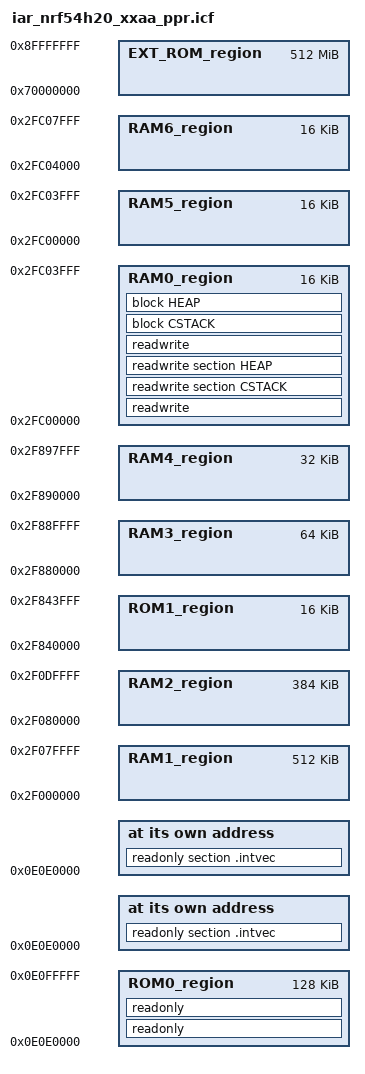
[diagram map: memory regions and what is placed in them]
/*###ICF### Section handled by ICF editor, don't touch! ****/
/*-Editor annotation file-*/
/* IcfEditorFile="$TOOLKIT_DIR$\config\ide\IcfEditor\cortex_v1_0.xml" */
/*-Specials-*/
define symbol __ICFEDIT_intvec_start__ = 0x0E0E0000;
/*-Memory Regions-*/
define symbol __ICFEDIT_region_ROM0_start__   = 0x0E0E0000;
define symbol __ICFEDIT_region_ROM0_end__     = 0x0E0FFFFF;
define symbol __ICFEDIT_region_ROM1_start__   = 0x2F840000;
define symbol __ICFEDIT_region_ROM1_end__     = 0x2F843FFF;
define symbol __ICFEDIT_region_EXT_ROM_start__   = 0x70000000;
define symbol __ICFEDIT_region_EXT_ROM_end__     = 0x8FFFFFFF;
define symbol __ICFEDIT_region_RAM0_start__   = 0x2FC00000;
define symbol __ICFEDIT_region_RAM0_end__     = 0x2FC03FFF;
define symbol __ICFEDIT_region_RAM1_start__   = 0x2F000000;
define symbol __ICFEDIT_region_RAM1_end__     = 0x2F07FFFF;
define symbol __ICFEDIT_region_RAM2_start__   = 0x2F080000;
define symbol __ICFEDIT_region_RAM2_end__     = 0x2F0DFFFF;
define symbol __ICFEDIT_region_RAM3_start__   = 0x2F880000;
define symbol __ICFEDIT_region_RAM3_end__     = 0x2F88FFFF;
define symbol __ICFEDIT_region_RAM4_start__   = 0x2F890000;
define symbol __ICFEDIT_region_RAM4_end__     = 0x2F897FFF;
define symbol __ICFEDIT_region_RAM5_start__   = 0x2FC00000;
define symbol __ICFEDIT_region_RAM5_end__     = 0x2FC03FFF;
define symbol __ICFEDIT_region_RAM6_start__   = 0x2FC04000;
define symbol __ICFEDIT_region_RAM6_end__     = 0x2FC07FFF;

/*-Sizes-*/
define symbol __ICFEDIT_size_cstack__   = 0x800;
define symbol __ICFEDIT_size_heap__     = 0x800;
/**** End of ICF editor section. ###ICF###*/

define memory mem with size = 4G;
define region ROM0_region = mem:[from __ICFEDIT_region_ROM0_start__   to __ICFEDIT_region_ROM0_end__]; /* Inside global MRAM0 */
define region ROM1_region = mem:[from __ICFEDIT_region_ROM1_start__   to __ICFEDIT_region_ROM1_end__]; /* OTP0 */
define region EXT_ROM_region = mem:[from __ICFEDIT_region_EXT_ROM_start__   to __ICFEDIT_region_EXT_ROM_end__];
define region RAM0_region = mem:[from __ICFEDIT_region_RAM0_start__   to __ICFEDIT_region_RAM0_end__]; /* All of GRAM30 */
define region RAM1_region = mem:[from __ICFEDIT_region_RAM1_start__   to __ICFEDIT_region_RAM1_end__]; /* RAM00 */
define region RAM2_region = mem:[from __ICFEDIT_region_RAM2_start__   to __ICFEDIT_region_RAM2_end__]; /* RAM01 */
define region RAM3_region = mem:[from __ICFEDIT_region_RAM3_start__   to __ICFEDIT_region_RAM3_end__]; /* RAM20 */
define region RAM4_region = mem:[from __ICFEDIT_region_RAM4_start__   to __ICFEDIT_region_RAM4_end__]; /* RAM21 */
define region RAM5_region = mem:[from __ICFEDIT_region_RAM5_start__   to __ICFEDIT_region_RAM5_end__]; /* RAM30 (low-speed) */
define region RAM6_region = mem:[from __ICFEDIT_region_RAM6_start__   to __ICFEDIT_region_RAM6_end__]; /* RAM31 (low-speed) */


if (isdefinedsymbol(__STARTUP_CONFIG)) {

    /* CSTACK and HEAP sections defined in startup file. */
    keep { section CSTACK };
    keep { section HEAP };

    initialize by copy { readwrite };
    do not initialize  { section .noinit };
    do not initialize  { section CSTACK };
    do not initialize  { section HEAP };

    place at address mem:__ICFEDIT_intvec_start__ { readonly section .intvec };
    place in ROM0_region   { readonly };
    place in RAM0_region   { readwrite, readwrite section CSTACK, readwrite section HEAP };

} else {

    define block CSTACK    with alignment = 8, size = __ICFEDIT_size_cstack__   { };
    define block HEAP      with alignment = 8, size = __ICFEDIT_size_heap__     { };

    initialize by copy { readwrite };
    do not initialize  { section .noinit };

    place at address mem:__ICFEDIT_intvec_start__ { readonly section .intvec };
    place in ROM0_region   { readonly };
    place in RAM0_region   { readwrite, block CSTACK, block HEAP };

}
